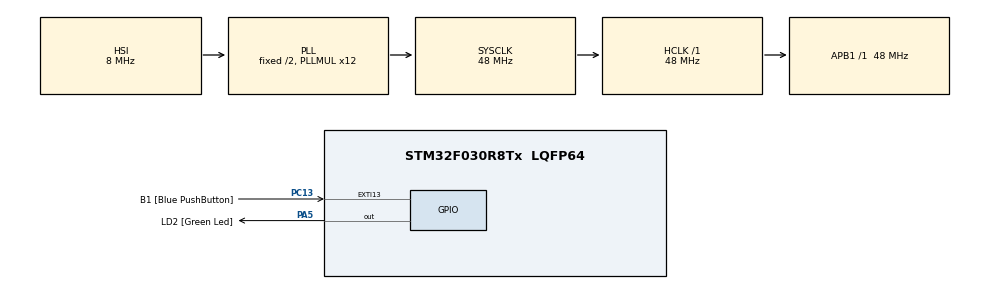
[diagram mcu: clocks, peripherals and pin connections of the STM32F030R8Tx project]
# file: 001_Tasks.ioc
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FREERTOS.Tasks01=defaultTask,0,128,StartDefaultTask,Default,NULL,Dynamic,NULL,NULL
Mcu.Family=STM32F0
Mcu.Name=STM32F030R8Tx
Mcu.Package=LQFP64
NVIC.TIM6_IRQn=true\:0\:0\:false\:false\:true\:false\:false\:true
NVIC.TimeBase=TIM6_IRQn
NVIC.TimeBaseIP=TIM6
PA13.GPIO_Label=TMS
PA13.Signal=SYS_SWDIO
PA14.GPIO_Label=TCK
PA14.Signal=SYS_SWCLK
PA2.GPIO_Label=USART_TX
PA2.GPIO_Mode=GPIO_MODE_AF_PP
PA2.GPIO_PuPd=GPIO_NOPULL
PA2.GPIO_Speed=GPIO_SPEED_FREQ_LOW
PA2.Signal=USART2_TX
PA3.GPIO_Label=USART_RX
PA3.GPIO_Mode=GPIO_MODE_AF_PP
PA3.GPIO_PuPd=GPIO_NOPULL
PA3.GPIO_Speed=GPIO_SPEED_FREQ_LOW
PA3.Signal=USART2_RX
PA5.GPIO_Label=LD2 [Green Led]
PA5.GPIO_Mode=GPIO_MODE_OUTPUT_PP
PA5.GPIO_PuPd=GPIO_NOPULL
PA5.GPIO_Speed=GPIO_SPEED_FREQ_LOW
PA5.Signal=GPIO_Output
PC13.GPIO_Label=B1 [Blue PushButton]
PC13.GPIO_ModeDefaultEXTI=GPIO_MODE_IT_FALLING
PC13.Signal=GPXTI13
PC14-OSC32_IN.Signal=RCC_OSC32_IN
PC15-OSC32_OUT.Signal=RCC_OSC32_OUT
PF0-OSC_IN.Signal=RCC_OSC_IN
PF1-OSC_OUT.Signal=RCC_OSC_OUT
ProjectManager.HeapSize=0x200
ProjectManager.StackSize=0x400
ProjectManager.TargetToolchain=STM32CubeIDE
RCC.AHBFreq_Value=48000000
RCC.APB1Freq_Value=48000000
RCC.APB1TimFreq_Value=48000000
RCC.HCLKFreq_Value=48000000
RCC.PLLMUL=RCC_PLL_MUL12
RCC.SYSCLKFreq_VALUE=48000000
RCC.SYSCLKSource=RCC_SYSCLKSOURCE_PLLCLK
VP_FREERTOS_VS_CMSIS_V1.Mode=CMSIS_V1
VP_SYS_VS_tim6.Mode=TIM6
board=NUCLEO-F030R8

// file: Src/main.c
/* USER CODE BEGIN Header */
/**
  ******************************************************************************
  * @file           : main.c
  * @brief          : Main program body
  ******************************************************************************
  * @attention
  *
  * <h2><center>&copy; Copyright (c) 2022 STMicroelectronics.
  * All rights reserved.</center></h2>
  *
  * This software component is licensed by ST under BSD 3-Clause license,
  * the "License"; You may not use this file except in compliance with the
  * License. You may obtain a copy of the License at:
  *                        opensource.org/licenses/BSD-3-Clause
  *
  ******************************************************************************
  */
/* USER CODE END Header */

#include "main.h"
#include "cmsis_os.h"

/* USER CODE BEGIN Includes */
#include "stdio.h"
#include "FreeRTOS.h"
#include "task.h"

/* USER CODE END Includes */

/* USER CODE BEGIN PD */
void shieldConfig(){
    #define RCC_AHBENR (*(unsigned int*) (0x40021014)) //de clock
	#define GPIOB_MODER (*(unsigned int*) (0x48000400)) // mode register
	#define GPIOB_ODR (*(unsigned int*) (0x48000414)) // output data register
	#define PUPDR (*(unsigned int*) (0x4800040C)) // Pull up/Pull down register
	#define GPIOB_IDR (*(unsigned int*) (0x48000410)) //input data register

	RCC_AHBENR |= (1 << 18);
	GPIOB_MODER |= 0x1540;
	PUPDR |= (1 << 19);
}

/* USER CODE END PD */

osThreadId defaultTaskHandle;

void SystemClock_Config(void);
static void MX_GPIO_Init(void);
void StartDefaultTask(void const * argument);

/* USER CODE BEGIN PFP */
static void task1_handler(void* parameters);
static void task2_handler(void* parameters);

/* USER CODE END PFP */

int main(void)
{
  /* USER CODE BEGIN 1 */
TaskHandle_t task1_handle;
TaskHandle_t task2_handle;

BaseType_t status;

shieldConfig();
  /* USER CODE END 1 */

  /* MCU Configuration--------------------------------------------------------*/

  /* Reset of all peripherals, Initializes the Flash interface and the Systick. */
  HAL_Init();

  /* Configure the system clock */
  SystemClock_Config();

  /* Initialize all configured peripherals */
  MX_GPIO_Init();
  /* USER CODE BEGIN 2 */

  status = xTaskCreate(task1_handler, "Task_1", 200, "Hello World from task 1", 2, &task1_handle );

  configASSERT(status == pdPASS);

  status = xTaskCreate(task2_handler, "Task_2", 200, "Hello World from task 2", 2, &task2_handle );

  configASSERT(status == pdPASS);

  // start the freertos scheduler

  vTaskStartScheduler();
  /* USER CODE END 2 */

  /* Create the thread(s) */
  /* definition and creation of defaultTask */
  osThreadDef(defaultTask, StartDefaultTask, osPriorityNormal, 0, 128);
  defaultTaskHandle = osThreadCreate(osThread(defaultTask), NULL);

  /* Start scheduler */
  osKernelStart();

  /* We should never get here as control is now taken by the scheduler */
  /* Infinite loop */
  while (1)
  {

  }
}

void SystemClock_Config(void)
{
  RCC_OscInitTypeDef RCC_OscInitStruct = {0};
  RCC_ClkInitTypeDef RCC_ClkInitStruct = {0};

  /** Initializes the CPU, AHB and APB busses clocks
  */
  RCC_OscInitStruct.OscillatorType = RCC_OSCILLATORTYPE_HSI;
  RCC_OscInitStruct.HSIState = RCC_HSI_ON;
  RCC_OscInitStruct.HSICalibrationValue = RCC_HSICALIBRATION_DEFAULT;
  RCC_OscInitStruct.PLL.PLLState = RCC_PLL_ON;
  RCC_OscInitStruct.PLL.PLLSource = RCC_PLLSOURCE_HSI;
  RCC_OscInitStruct.PLL.PLLMUL = RCC_PLL_MUL12;
  RCC_OscInitStruct.PLL.PREDIV = RCC_PREDIV_DIV1;
  if (HAL_RCC_OscConfig(&RCC_OscInitStruct) != HAL_OK)
  {
    Error_Handler();
  }
  /** Initializes the CPU, AHB and APB busses clocks
  */
  RCC_ClkInitStruct.ClockType = RCC_CLOCKTYPE_HCLK|RCC_CLOCKTYPE_SYSCLK
                              |RCC_CLOCKTYPE_PCLK1;
  RCC_ClkInitStruct.SYSCLKSource = RCC_SYSCLKSOURCE_PLLCLK;
  RCC_ClkInitStruct.AHBCLKDivider = RCC_SYSCLK_DIV1;
  RCC_ClkInitStruct.APB1CLKDivider = RCC_HCLK_DIV1;

  if (HAL_RCC_ClockConfig(&RCC_ClkInitStruct, FLASH_LATENCY_1) != HAL_OK)
  {
    Error_Handler();
  }
}

static void MX_GPIO_Init(void)
{
  GPIO_InitTypeDef GPIO_InitStruct = {0};

  /* GPIO Ports Clock Enable */
  __HAL_RCC_GPIOC_CLK_ENABLE();
  __HAL_RCC_GPIOF_CLK_ENABLE();
  __HAL_RCC_GPIOA_CLK_ENABLE();

  /*Configure GPIO pin Output Level */
  HAL_GPIO_WritePin(LD2_GPIO_Port, LD2_Pin, GPIO_PIN_RESET);

  /*Configure GPIO pin : B1_Pin */
  GPIO_InitStruct.Pin = B1_Pin;
  GPIO_InitStruct.Mode = GPIO_MODE_IT_FALLING;
  GPIO_InitStruct.Pull = GPIO_NOPULL;
  HAL_GPIO_Init(B1_GPIO_Port, &GPIO_InitStruct);

  /*Configure GPIO pins : USART_TX_Pin USART_RX_Pin */
  GPIO_InitStruct.Pin = USART_TX_Pin|USART_RX_Pin;
  GPIO_InitStruct.Mode = GPIO_MODE_AF_PP;
  GPIO_InitStruct.Pull = GPIO_NOPULL;
  GPIO_InitStruct.Speed = GPIO_SPEED_FREQ_LOW;
  GPIO_InitStruct.Alternate = GPIO_AF1_USART2;
  HAL_GPIO_Init(GPIOA, &GPIO_InitStruct);

  /*Configure GPIO pin : LD2_Pin */
  GPIO_InitStruct.Pin = LD2_Pin;
  GPIO_InitStruct.Mode = GPIO_MODE_OUTPUT_PP;
  GPIO_InitStruct.Pull = GPIO_NOPULL;
  GPIO_InitStruct.Speed = GPIO_SPEED_FREQ_LOW;
  HAL_GPIO_Init(LD2_GPIO_Port, &GPIO_InitStruct);

}

/* USER CODE BEGIN 4 */

static void task1_handler(void* parameters)
{

while(1){
						GPIOB_ODR |= 0x8;
						//GPIOB_ODR |= 0x20;
						//GPIOB_ODR |= 0x10;
					//	GPIOB_ODR |= 0x40;

}

}

static void task2_handler(void* parameters)
{
	while(1){
							//GPIOB_ODR |= 0x8;
							//GPIOB_ODR |= 0x20;
							//GPIOB_ODR |= 0x10;
							GPIOB_ODR |= 0x40;

	}

}

/* USER CODE END 4 */

void StartDefaultTask(void const * argument)
{
  for(;;)
  {
    osDelay(1);
  }
}

 /**
  * @brief  Period elapsed callback in non blocking mode
  * @note   This function is called  when TIM6 interrupt took place, inside
  * HAL_TIM_IRQHandler(). It makes a direct call to HAL_IncTick() to increment
  * a global variable "uwTick" used as application time base.
  * @param  htim : TIM handle
  * @retval None
  */
void HAL_TIM_PeriodElapsedCallback(TIM_HandleTypeDef *htim)
{
  if (htim->Instance == TIM6) {
    HAL_IncTick();
  }
}

void Error_Handler(void)
{
}

/************************ (C) COPYRIGHT STMicroelectronics *****END OF FILE****/
